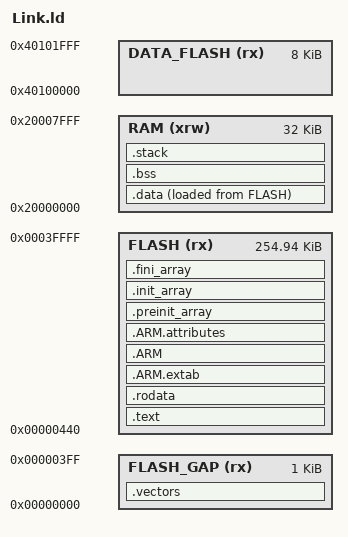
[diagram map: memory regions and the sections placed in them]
RAM_START = 0x20000000;
RAM_LENGTH = 0x00008000;
FLASH_START = 0x00000440;
FLASH_LENGTH = 0x0003fbc0;
DATA_FLASH_START = 0x40100000;
DATA_FLASH_LENGTH = 0x00002000;
FLASH_GAP_START = 0x00000000;
FLASH_GAP_LENGTH = 0x00000400;

ENTRY(_start)

__stack_size = 2048;

PROVIDE( _stack_size = __stack_size );

/* memory map */
MEMORY
{
  FLASH    (rx): ORIGIN = FLASH_START, LENGTH = FLASH_LENGTH
  RAM      (xrw): ORIGIN = RAM_START, LENGTH = RAM_LENGTH
  DATA_FLASH (rx) : ORIGIN = DATA_FLASH_START, LENGTH = DATA_FLASH_LENGTH
  FLASH_GAP (rx) : ORIGIN = FLASH_GAP_START, LENGTH = FLASH_GAP_LENGTH
}

SECTIONS
{
  /* ISR vectors */
  .vectors :
  {
    . = ALIGN(4);
    KEEP(*(.vectors))
    . = ALIGN(4);
    __Vectors_End = .;
    __Vectors_Size = __Vectors_End - __gVectors;
  } >FLASH_GAP

  /* text section, such as program code */
  .text :
  {
    . = ALIGN(4);
    *(.text)
    *(.text*)
    *(.glue_7)
    *(.glue_7t)
    *(.eh_frame)
    KEEP (*(.init))
    KEEP (*(.fini))
    . = ALIGN(4);
    /* the symbol '_etext' will be defined at the end of code section */
    _etext = .;
  } >FLASH

  /* ro-data section, such as constant data */
  .rodata :
  {
    . = ALIGN(4);
    *(.rodata)
    *(.rodata*)
    . = ALIGN(4);
  } >FLASH

  /* exception process table */
  .ARM.extab :
  {
    *(.ARM.extab* .gnu.linkonce.armextab.*)
  } >FLASH

  /* exception process table index */
  .ARM :
  {
    __exidx_start = .;
    *(.ARM.exidx*)
    __exidx_end = .;
  } >FLASH

  /* ARM attributes */
  .ARM.attributes :
  {
   *(.ARM.attributes)
  } >FLASH

  .preinit_array :
  {
    PROVIDE_HIDDEN (__preinit_array_start = .);
    KEEP (*(.preinit_array*))
    PROVIDE_HIDDEN (__preinit_array_end = .);
  } >FLASH

  .init_array :
  {
    PROVIDE_HIDDEN (__init_array_start = .);
    KEEP (*(SORT(.init_array.*)))
    KEEP (*(.init_array*))
    PROVIDE_HIDDEN (__init_array_end = .);
  } >FLASH

  .fini_array :
  {
    PROVIDE_HIDDEN (__fini_array_start = .);
    KEEP (*(.fini_array*))
    KEEP (*(SORT(.fini_array.*)))
    PROVIDE_HIDDEN (__fini_array_end = .);
  } >FLASH

  /* provide some necessary symbols for initialized data */
  _sidata = LOADADDR(.data);
  .data :
  {
    . = ALIGN(4);
    /* the symbol '_sdata' will be defined at the data section end start */
    _sdata = .;
    *(.data)
    *(.data*)
    . = ALIGN(4);
    /* the symbol '_edata' will be defined at the data section end */
    _edata = .;
  } > RAM AT> FLASH

  /* provide some necessary symbols for uninitialized data */
  . = ALIGN(4);
  .bss :
  {
    . = ALIGN(4);
    /* the symbol '_sbss' will be defined at the bss section start */
    _sbss = .;
    __bss_start__ = _sbss;
    *(.bss)
    *(.bss*)
    *(COMMON)
    . = ALIGN(4);
    /* the symbol '_ebss' will be defined at the bss section end */
    _ebss = .;
    __bss_end__ = _ebss;
  } > RAM

  PROVIDE( _end = _ebss);
  PROVIDE( end = . );

  .stack ORIGIN(RAM) + LENGTH(RAM) - __stack_size :
  {
      PROVIDE( _heap_end = . );
      . = ALIGN(4);
      . = . + __stack_size;
      PROVIDE( _sp = .);
  } >RAM

  .ARM.attributes 0 : { *(.ARM.attributes) }
}
